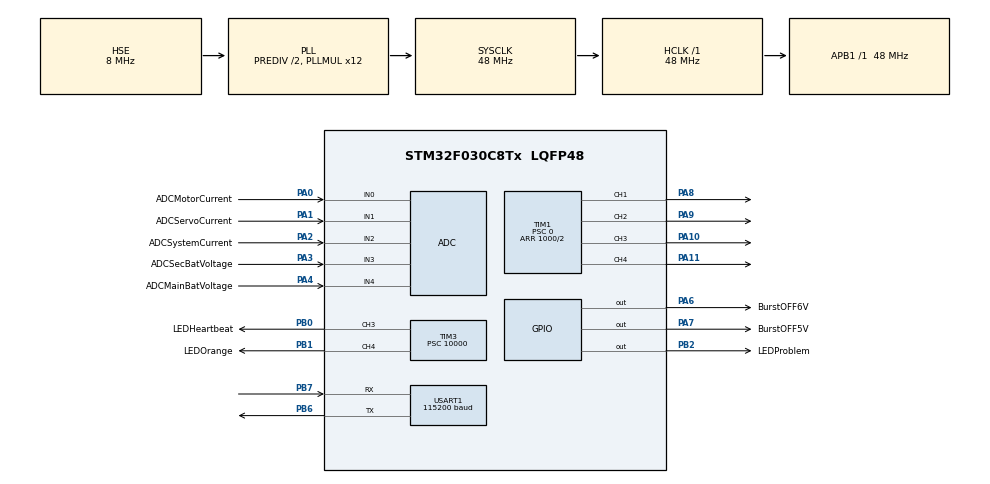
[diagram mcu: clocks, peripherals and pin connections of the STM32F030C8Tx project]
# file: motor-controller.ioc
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ADC.ClockPrescaler=ADC_CLOCK_SYNC_PCLK_DIV4
Mcu.Family=STM32F0
Mcu.Name=STM32F030C8Tx
Mcu.Package=LQFP48
NVIC.ADC1_IRQn=true\:0\:0\:false\:false\:true\:true
NVIC.TIM1_BRK_UP_TRG_COM_IRQn=true\:0\:0\:false\:false\:true\:true
NVIC.TIM6_IRQn=true\:0\:0\:false\:false\:true\:true
NVIC.USART1_IRQn=true\:0\:0\:false\:false\:true\:true
PA0.GPIO_Label=ADCMotorCurrent
PA0.Mode=IN0
PA0.Signal=ADC_IN0
PA1.GPIO_Label=ADCServoCurrent
PA1.Mode=IN1
PA1.Signal=ADC_IN1
PA10.Signal=S_TIM1_CH3
PA11.Signal=S_TIM1_CH4
PA13.Mode=Serial_Wire
PA13.Signal=SYS_SWDIO
PA14.Mode=Serial_Wire
PA14.Signal=SYS_SWCLK
PA2.GPIO_Label=ADCSystemCurrent
PA2.Mode=IN2
PA2.Signal=ADC_IN2
PA3.GPIO_Label=ADCSecBatVoltage
PA3.Mode=IN3
PA3.Signal=ADC_IN3
PA4.GPIO_Label=ADCMainBatVoltage
PA4.Mode=IN4
PA4.Signal=ADC_IN4
PA6.GPIO_Label=BurstOFF6V
PA6.Signal=GPIO_Output
PA7.GPIO_Label=BurstOFF5V
PA7.Signal=GPIO_Output
PA8.Signal=S_TIM1_CH1
PA9.Signal=S_TIM1_CH2
PB0.GPIO_Label=LEDHeartbeat
PB0.Signal=S_TIM3_CH3
PB1.GPIO_Label=LEDOrange
PB1.Signal=S_TIM3_CH4
PB2.GPIO_Label=LEDProblem
PB2.Signal=GPIO_Output
PB6.Mode=Asynchronous
PB6.Signal=USART1_TX
PB7.Mode=Asynchronous
PB7.Signal=USART1_RX
PF0-OSC_IN.Mode=HSE-External-Oscillator
PF0-OSC_IN.Signal=RCC_OSC_IN
PF1-OSC_OUT.Mode=HSE-External-Oscillator
PF1-OSC_OUT.Signal=RCC_OSC_OUT
ProjectManager.HeapSize=0x200
ProjectManager.StackSize=0x400
ProjectManager.TargetToolchain=TrueSTUDIO
RCC.AHBFreq_Value=48000000
RCC.APB1Freq_Value=48000000
RCC.APB1TimFreq_Value=48000000
RCC.HCLKFreq_Value=48000000
RCC.I2c1ClockSelection=RCC_I2C1CLKSOURCE_SYSCLK
RCC.PLLDivider=RCC_PREDIV_DIV2
RCC.PLLMUL=RCC_PLL_MUL12
RCC.PLLSourceVirtual=RCC_PLLSOURCE_HSE
RCC.SYSCLKFreq_VALUE=48000000
RCC.SYSCLKSource=RCC_SYSCLKSOURCE_PLLCLK
SH.S_TIM1_CH1.0=TIM1_CH1,PWM Generation1 CH1
SH.S_TIM1_CH2.0=TIM1_CH2,PWM Generation2 CH2
SH.S_TIM1_CH3.0=TIM1_CH3,PWM Generation3 CH3
SH.S_TIM1_CH4.0=TIM1_CH4,PWM Generation4 CH4
SH.S_TIM3_CH3.0=TIM3_CH3,PWM Generation3 CH3
SH.S_TIM3_CH4.0=TIM3_CH4,PWM Generation4 CH4
TIM1.Channel-PWM\ Generation1\ CH1=TIM_CHANNEL_1
TIM1.Channel-PWM\ Generation2\ CH2=TIM_CHANNEL_2
TIM1.Channel-PWM\ Generation3\ CH3=TIM_CHANNEL_3
TIM1.Channel-PWM\ Generation4\ CH4=TIM_CHANNEL_4
TIM1.CounterMode=TIM_COUNTERMODE_CENTERALIGNED1
TIM1.OCPolarity_1=TIM_OCPOLARITY_HIGH
TIM1.OCPolarity_2=TIM_OCPOLARITY_LOW
TIM1.OCPolarity_3=TIM_OCPOLARITY_HIGH
TIM1.OCPolarity_4=TIM_OCPOLARITY_LOW
TIM1.Period=1000/2
TIM1.Prescaler=0
TIM1.Pulse-PWM\ Generation1\ CH1=600
TIM1.Pulse-PWM\ Generation2\ CH2=600
TIM3.Channel-PWM\ Generation3\ CH3=TIM_CHANNEL_3
TIM3.Channel-PWM\ Generation4\ CH4=TIM_CHANNEL_4
TIM3.ClockDivision=TIM_CLOCKDIVISION_DIV4
TIM3.Period=2400
TIM3.Prescaler=10000
TIM6.Period=20000-1
TIM6.Prescaler=48-1
USART1.BaudRate=115200
USART1.VirtualMode-Asynchronous=VM_ASYNC
VP_TIM6_VS_ClockSourceINT.Mode=Enable_Timer
board=custom

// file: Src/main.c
/* USER CODE BEGIN Header */
/**
  ******************************************************************************
  * @file           : main.c
  * @brief          : Main program body
  ******************************************************************************
  ** This notice applies to any and all portions of this file
  * that are not between comment pairs USER CODE BEGIN and
  * USER CODE END. Other portions of this file, whether
  * inserted by the user or by software development tools
  * are owned by their respective copyright owners.
  *
  * COPYRIGHT(c) 2019 STMicroelectronics
  *
  * Redistribution and use in source and binary forms, with or without modification,
  * are permitted provided that the following conditions are met:
  *   1. Redistributions of source code must retain the above copyright notice,
  *      this list of conditions and the following disclaimer.
  *   2. Redistributions in binary form must reproduce the above copyright notice,
  *      this list of conditions and the following disclaimer in the documentation
  *      and/or other materials provided with the distribution.
  *   3. Neither the name of STMicroelectronics nor the names of its contributors
  *      may be used to endorse or promote products derived from this software
  *      without specific prior written permission.
  *
  * THIS SOFTWARE IS PROVIDED BY THE COPYRIGHT HOLDERS AND CONTRIBUTORS "AS IS"
  * AND ANY EXPRESS OR IMPLIED WARRANTIES, INCLUDING, BUT NOT LIMITED TO, THE
  * IMPLIED WARRANTIES OF MERCHANTABILITY AND FITNESS FOR A PARTICULAR PURPOSE ARE
  * DISCLAIMED. IN NO EVENT SHALL THE COPYRIGHT HOLDER OR CONTRIBUTORS BE LIABLE
  * FOR ANY DIRECT, INDIRECT, INCIDENTAL, SPECIAL, EXEMPLARY, OR CONSEQUENTIAL
  * DAMAGES (INCLUDING, BUT NOT LIMITED TO, PROCUREMENT OF SUBSTITUTE GOODS OR
  * SERVICES; LOSS OF USE, DATA, OR PROFITS; OR BUSINESS INTERRUPTION) HOWEVER
  * CAUSED AND ON ANY THEORY OF LIABILITY, WHETHER IN CONTRACT, STRICT LIABILITY,
  * OR TORT (INCLUDING NEGLIGENCE OR OTHERWISE) ARISING IN ANY WAY OUT OF THE USE
  * OF THIS SOFTWARE, EVEN IF ADVISED OF THE POSSIBILITY OF SUCH DAMAGE.
  *
  ******************************************************************************
  */
/* USER CODE END Header */

#include "main.h"
#include "adc.h"
#include "tim.h"
#include "usart.h"
#include "gpio.h"

/* USER CODE BEGIN Includes */

#include "app_applicaton.h"
#include "app_init.h"

/* USER CODE END Includes */

/* USER CODE BEGIN PV */
/* Private variables ---------------------------------------------------------*/

/* USER CODE END PV */

void SystemClock_Config(void);
/* USER CODE BEGIN PFP */
/* Private function prototypes -----------------------------------------------*/

/* USER CODE END PFP */

int main(void)
{

  /* MCU Configuration--------------------------------------------------------*/

  /* Reset of all peripherals, Initializes the Flash interface and the Systick. */
  HAL_Init();

  /* Configure the system clock */
  SystemClock_Config();

  /* Initialize all configured peripherals */
  MX_GPIO_Init();
  MX_TIM1_Init();
  MX_ADC_Init();
  MX_USART1_UART_Init();
  MX_TIM3_Init();
  MX_TIM6_Init();

  /* Infinite loop */
  /* USER CODE BEGIN WHILE */

  APP_Init();

  while (1)
  {

    /* USER CODE END WHILE */

  }
}

void SystemClock_Config(void)
{
  RCC_OscInitTypeDef RCC_OscInitStruct = {0};
  RCC_ClkInitTypeDef RCC_ClkInitStruct = {0};
  RCC_PeriphCLKInitTypeDef PeriphClkInit = {0};

  /**Initializes the CPU, AHB and APB busses clocks
  */
  RCC_OscInitStruct.OscillatorType = RCC_OSCILLATORTYPE_HSE;
  RCC_OscInitStruct.HSEState = RCC_HSE_ON;
  RCC_OscInitStruct.PLL.PLLState = RCC_PLL_ON;
  RCC_OscInitStruct.PLL.PLLSource = RCC_PLLSOURCE_HSE;
  RCC_OscInitStruct.PLL.PLLMUL = RCC_PLL_MUL12;
  RCC_OscInitStruct.PLL.PREDIV = RCC_PREDIV_DIV2;
  if (HAL_RCC_OscConfig(&RCC_OscInitStruct) != HAL_OK)
  {
    Error_Handler();
  }
  /**Initializes the CPU, AHB and APB busses clocks
  */
  RCC_ClkInitStruct.ClockType = RCC_CLOCKTYPE_HCLK|RCC_CLOCKTYPE_SYSCLK
                              |RCC_CLOCKTYPE_PCLK1;
  RCC_ClkInitStruct.SYSCLKSource = RCC_SYSCLKSOURCE_PLLCLK;
  RCC_ClkInitStruct.AHBCLKDivider = RCC_SYSCLK_DIV1;
  RCC_ClkInitStruct.APB1CLKDivider = RCC_HCLK_DIV1;

  if (HAL_RCC_ClockConfig(&RCC_ClkInitStruct, FLASH_LATENCY_1) != HAL_OK)
  {
    Error_Handler();
  }
  PeriphClkInit.PeriphClockSelection = RCC_PERIPHCLK_USART1;
  PeriphClkInit.Usart1ClockSelection = RCC_USART1CLKSOURCE_PCLK1;
  if (HAL_RCCEx_PeriphCLKConfig(&PeriphClkInit) != HAL_OK)
  {
    Error_Handler();
  }
}

void Error_Handler(void)
{
  while(1)
  {
  }
}

/************************ (C) COPYRIGHT STMicroelectronics *****END OF FILE****/
